# STM32MP23_CM33 register map
File version: 1.2
CPU: CM33 r0p1, little endian, MPU, FPU, vendor SysTick, 8 interrupt priority bits
Registers are 32-bit, read-write, reset 0x0 unless marked. A register's access mark holds for its fields unless they carry their own. Offsets are from the block's base; [hi:lo] are bit positions; lines under a group give offsets from that group; {n}, {i} and the like mark numbered series.

## GICH — GICH address block description
Base 0x4AC40000
Same registers: GICH_S 0x5AC40000
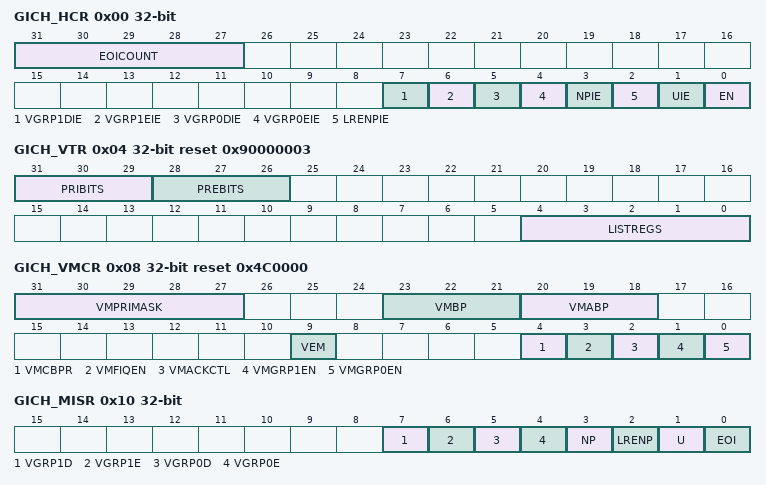
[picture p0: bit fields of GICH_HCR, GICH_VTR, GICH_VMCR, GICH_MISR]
0x00 GICH_HCR — GICH hypervisor control register
  [31:27] EOICOUNT — End-of-interrupt counter
  [7] VGRP1DIE — Virtual machine disable group 1 interrupt enable
  [6] VGRP1EIE — Virtual machine enable group 1 interrupt enable
  [5] VGRP0DIE — Virtual machine disable group 0 interrupt enable
  [4] VGRP0EIE — Virtual machine enable group 0interrupt enable
  [3] NPIE — No pending interrupt enable
  [2] LRENPIE — List register entry not present interrupt enable
  [1] UIE — Underflow interrupt enable.
  [0] EN — Global enable bit for the virtual CPU interface
0x04 GICH_VTR ro reset 0x90000003 — GICH VGIC type register
  [31:29] PRIBITS — Priority bits
  [28:26] PREBITS — Preemption bits
  [4:0] LISTREGS — List registers
0x08 GICH_VMCR reset 0x4C0000 — GICH virtual machine control register
  [31:27] VMPRIMASK — Alias of GICV_PMR.PRIORITY
  [23:21] VMBP — Alias of GICV_BPR.BINARY_POINT
  [20:18] VMABP — Alias of GICV_ABPR.BINARY_POINT.
  [9] VEM — Alias of GICV_CTLR.EOIMODE
  [4] VMCBPR — Alias of GICV_CTLR.CBPR
  [3] VMFIQEN — Alias of GICV_CTLR.FIQEN
  [2] VMACKCTL — Alias of GICV_CTLR.ACKCTL
  [1] VMGRP1EN — Alias of GICV_CTLR.ENABLEGRP1
  [0] VMGRP0EN — Alias of GICV_CTLR.ENABLEGRP0
0x10 GICH_MISR ro — GICH maintenance interrupt status register
  [7] VGRP1D — Disabled group 1 maintenance interrupt
  [6] VGRP1E — Enabled group 1 maintenance interrupt
  [5] VGRP0D — Disabled group 0 maintenance interrupt
  [4] VGRP0E — Enabled group 0 maintenance interrupt
  [3] NP — No pending maintenance interrupt
  [2] LRENP — List register entry not present maintenance interrupt
  [1] U — Underflow maintenance interrupt
  [0] EOI — End of interrupt maintenance interrupt
0x20 GICH_EISR0 ro (reset mask 0xF) — GICH end of interrupt status register
  [31:0] EISR0 — End of interrupt status
0x30 GICH_ELSR0 ro reset 0xF (reset mask 0xF) — GICH empty list status register
  [31:0] ELSR0 — Empty list status
0xF0 GICH_APR0 — GICH active priority register
  [31:0] APR0 — Active priority
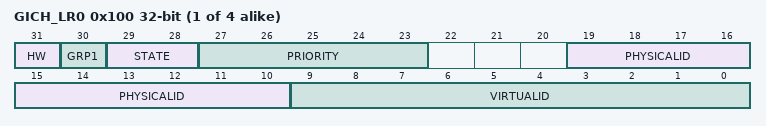
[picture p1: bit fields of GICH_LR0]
{0x100+4i} GICH_LR{i} (i=0..3) — GICH list register {i}
  [31] HW — Hardware interrupt
  [30] GRP1 — This bit indicates whether this virtual interrupt is a group 1 virtual interrupt.
  [29:28] STATE — State of the interrupt
  [27:23] PRIORITY — Priority of the interrupt
  [19:10] PHYSICALID
  [9:0] VIRTUALID

## HDP — HDP address block description
Base 0x44090000
Same registers: HDP_S 0x54090000
0x00 HDP_CTRL — HDP control register
  [0] EN — HDP enable (valid if enabled in BSEC)
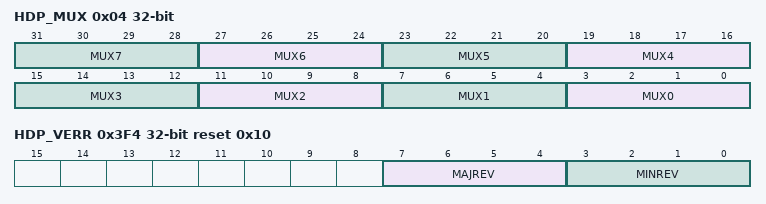
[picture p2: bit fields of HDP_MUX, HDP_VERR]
0x04 HDP_MUX — HDP multiplexer control register
  [4n+3:4n] MUX{n} (n=0..7) — Selection of the HDPy output among the 16 available signals
0x10 HDP_VAL ro — HDP read back value register
  [7:0] HDPVAL — Value of the HDP signals
0x14 HDP_GPOSET wo — HDP general purpose output set register
  [7:0] HDPGPOSET — When a bit is written to 1, the corresponding HDP GPO is set. Writing a bit to 0 has no effect.
0x18 HDP_GPOCLR wo — HDP general purpose output clear register
  [7:0] HDPGPOCLR — When a bit is written to 1, the corresponding HDP GPO is cleared. Writing a bit to 0 has no effect.
0x1C HDP_GPOVAL — HDP general purpose output value register
  [7:0] HDPGPOVAL — When written, this bit field defines the value of the HDP GPO. When read, this bit field provides the current GPO value.
0x3F4 HDP_VERR ro reset 0x10 — HDP version register
  [7:4] MAJREV — HDP major revision
  [3:0] MINREV — HDP minor revision
0x3F8 HDP_IPIDR ro reset 0x30002 — HDP identification register
  [31:0] ID — HDP identifier
0x3FC HDP_SIDR ro reset 0xA3C5DD01 — HDP size identification register
  [31:0] SID — Size identifier
